# Cortex_M55 register map
Vendor: ARM Ltd.; File version: 1.2
CPU: CM55 r0p0, little endian, MPU, FPU, vendor SysTick, 8 interrupt priority bits
Registers are 32-bit, read-write, no defined reset value unless marked. A register's access mark holds for its fields unless they carry their own. Offsets are from the block's base; [hi:lo] are bit positions; {n}, {i} and the like mark numbered series; 'fields as' and 'values as' point back to an identical list.

## FPE — Floating Point Control Registers
Base 0xE000EF34
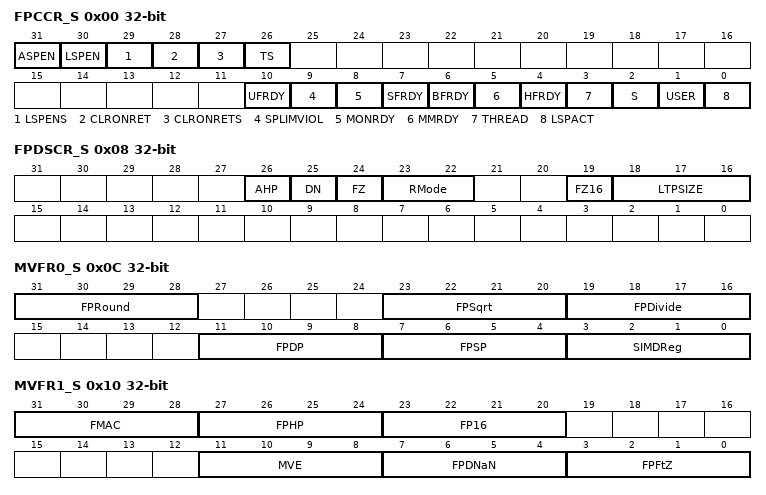
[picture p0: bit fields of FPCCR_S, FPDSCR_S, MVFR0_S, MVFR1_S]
0x00 FPCCR_S
  [31] ASPEN, [30] LSPEN, [29] LSPENS, [28] CLRONRET, [27] CLRONRETS, [26] TS, [10] UFRDY, [9] SPLIMVIOL, [8] MONRDY, [7] SFRDY, [6] BFRDY, [5] MMRDY, [4] HFRDY, [3] THREAD, [2] S, [1] USER, [0] LSPACT
0x04 FPCAR_S
  [31:3] ADDRESS
0x08 FPDSCR_S
  [26] AHP, [25] DN, [24] FZ, [23:22] RMode, [19] FZ16, [18:16] LTPSIZE
0x0C MVFR0_S ro
  [31:28] FPRound, [23:20] FPSqrt, [19:16] FPDivide, [11:8] FPDP, [7:4] FPSP, [3:0] SIMDReg
0x10 MVFR1_S ro
  [31:28] FMAC, [27:24] FPHP, [23:20] FP16, [11:8] MVE, [7:4] FPDNaN, [3:0] FPFtZ
0x14 MVFR2_S ro
  [7:4] FPMisc
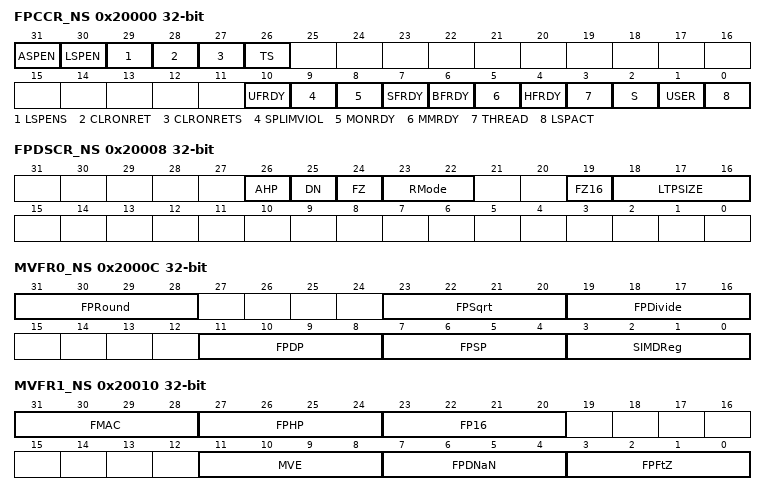
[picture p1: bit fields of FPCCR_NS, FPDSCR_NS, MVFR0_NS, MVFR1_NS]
0x20000 FPCCR_NS
  fields as FPCCR_S
0x20004 FPCAR_NS
  [31:3] ADDRESS
0x20008 FPDSCR_NS
  fields as FPDSCR_S
0x2000C MVFR0_NS ro
  fields as MVFR0_S
0x20010 MVFR1_NS ro
  fields as MVFR1_S
0x20014 MVFR2_NS ro
  [7:4] FPMisc

## ICB — Interrupt Control Registers
Base 0xE000E004
0x00 ICTR ro
  [3:0] INTLINESNUM
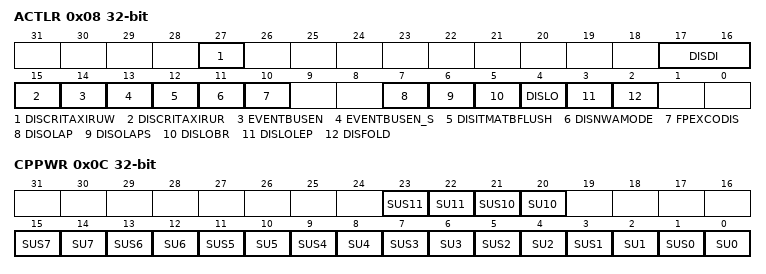
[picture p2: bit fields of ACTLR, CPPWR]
0x08 ACTLR
  [27] DISCRITAXIRUW, [17:16] DISDI, [15] DISCRITAXIRUR, [14] EVENTBUSEN, [13] EVENTBUSEN_S, [12] DISITMATBFLUSH, [11] DISNWAMODE, [10] FPEXCODIS, [7] DISOLAP, [6] DISOLAPS, [5] DISLOBR, [4] DISLO, [3] DISLOLEP, [2] DISFOLD
0x0C CPPWR
  [23] SUS11, [22] SU11, [21] SUS10, [20] SU10, [2n+1] SUS{n} (n=0..7), [2n] SU{n} (n=0..7)

## MPU — Memory protection Unit Control Registers
Base 0xE000ED90
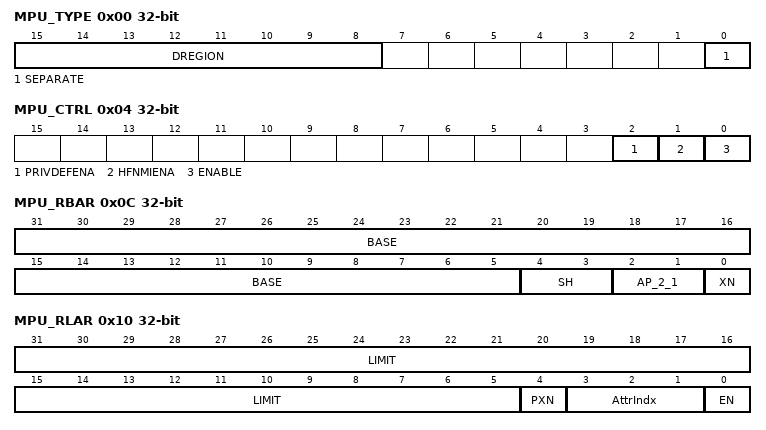
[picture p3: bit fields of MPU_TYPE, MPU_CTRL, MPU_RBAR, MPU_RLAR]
0x00 MPU_TYPE ro
  [15:8] DREGION
  [0] SEPARATE
    0=Uniform; 1=Separate
0x04 MPU_CTRL — MPU Control Register
  [2] PRIVDEFENA, [1] HFNMIENA, [0] ENABLE
0x08 MPU_RNR — MPU Region Number Register
  [7:0] REGION
0x0C MPU_RBAR — MPU Region Base Address Register
  [31:5] BASE, [4:3] SH, [2:1] AP_2_1, [0] XN
0x10 MPU_RLAR — MPU Region Limit Address Register
  [31:5] LIMIT, [4] PXN, [3:1] AttrIndx, [0] EN
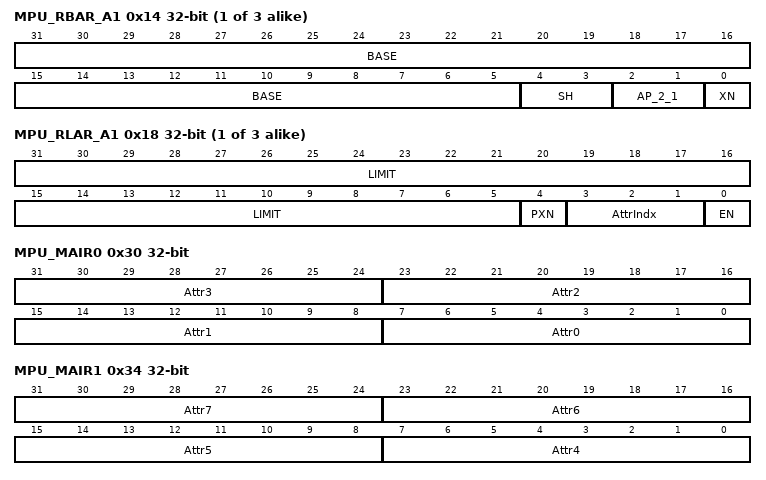
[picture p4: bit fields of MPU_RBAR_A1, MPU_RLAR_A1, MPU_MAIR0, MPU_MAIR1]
{0xC+8i} MPU_RBAR_A{i} (i=1..3) — MPU Region Base Address Register
  [31:5] BASE, [4:3] SH, [2:1] AP_2_1, [0] XN
{0x10+8i} MPU_RLAR_A{i} (i=1..3) — MPU Region Limit Address Register
  [31:5] LIMIT, [4] PXN, [3:1] AttrIndx, [0] EN
0x30 MPU_MAIR0 — MPU Memory Attribute Indirection Register 0
  [8n+7:8n] Attr{n} (n=0..3)
0x34 MPU_MAIR1 — MPU Memory Attribute Indirection Register 1
  [8n-25:8n-32] Attr{n} (n=4..7)
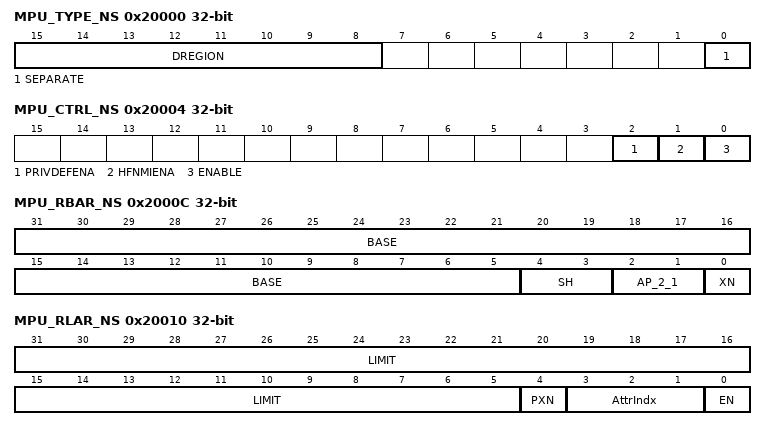
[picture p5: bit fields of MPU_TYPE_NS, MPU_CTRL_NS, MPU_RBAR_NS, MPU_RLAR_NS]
0x20000 MPU_TYPE_NS ro — MPU Type Register NS
  [15:8] DREGION
  [0] SEPARATE
    0=Uniform; 1=Separate
0x20004 MPU_CTRL_NS — MPU Control Register NS
  [2] PRIVDEFENA, [1] HFNMIENA, [0] ENABLE
0x20008 MPU_RNR_NS — MPU Region Number Register NS
  [7:0] REGION
0x2000C MPU_RBAR_NS — MPU Region Base Address Register NS
  [31:5] BASE, [4:3] SH, [2:1] AP_2_1, [0] XN
0x20010 MPU_RLAR_NS — MPU Region Limit Address Register NS
  [31:5] LIMIT, [4] PXN, [3:1] AttrIndx, [0] EN
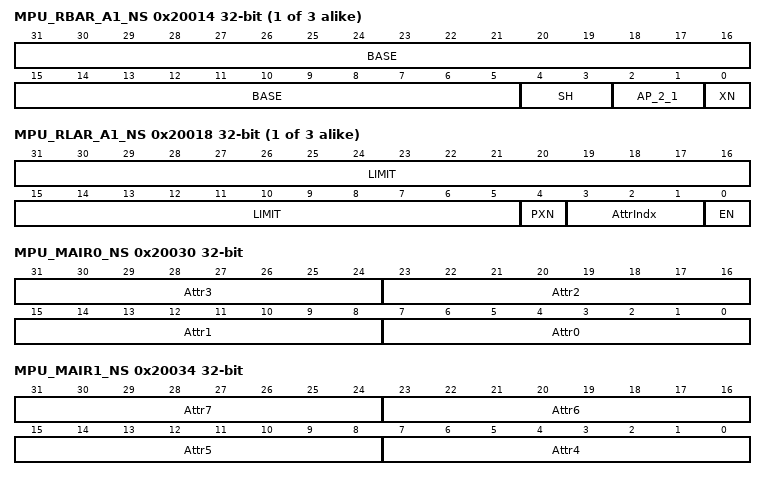
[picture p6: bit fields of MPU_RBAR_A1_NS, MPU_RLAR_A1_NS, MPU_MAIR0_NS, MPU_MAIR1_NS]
{0x2000C+8i} MPU_RBAR_A{i}_NS (i=1..3) — MPU Region Base Address Register NS
  [31:5] BASE, [4:3] SH, [2:1] AP_2_1, [0] XN
{0x20010+8i} MPU_RLAR_A{i}_NS (i=1..3) — MPU Region Limit Address Register NS
  [31:5] LIMIT, [4] PXN, [3:1] AttrIndx, [0] EN
0x20030 MPU_MAIR0_NS — MPU Memory Attribute Indirection Register 0 NS
  [8n+7:8n] Attr{n} (n=0..3)
0x20034 MPU_MAIR1_NS — MPU Memory Attribute Indirection Register 1 NS
  [8n-25:8n-32] Attr{n} (n=4..7)

## NVIC — Nested Vectored Interrupt Controller registers
Base 0xE000E100
{0x0+4i} NVIC_ISER{i} reset 0x0 (i=0..15) — Interrupt Set-Enable Register
  [31:0] SETENA
{0x80+4i} NVIC_ICER{i} reset 0x0 (i=0..15) — Interrupt Clear-Enable Register
  [31:0] CLRENA
{0x100+4i} NVIC_ISPR{i} reset 0x0 (i=0..15) — Interrupt Set-Pending Register
  [31:0] SETPEND
{0x180+4i} NVIC_ICPR{i} reset 0x0 (i=0..15) — Interrupt Clear-Pending Register
  [31:0] CLRPEND
{0x200+4i} NVIC_IABR{i} reset 0x0 (i=0..15) — Interrupt Active Bit Register
  [31:0] ACTIVE
{0x280+4i} ITNS{i} reset 0x0 (i=0..15) — Interrupt Target Non-secure Registers
  [31:0] ITNS
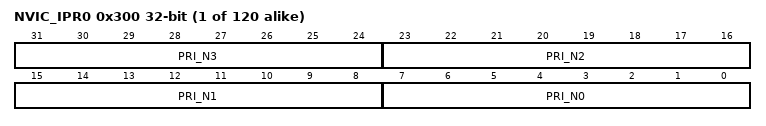
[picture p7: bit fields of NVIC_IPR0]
{0x300+4i} NVIC_IPR{i} (i=0..119)
  [8n+7:8n] PRI_N{n} (n=0..3)
0xE00 STIR ro
  [8:0] INTID

## SAU — Security Attribute Unit
Base 0xE000EDD0
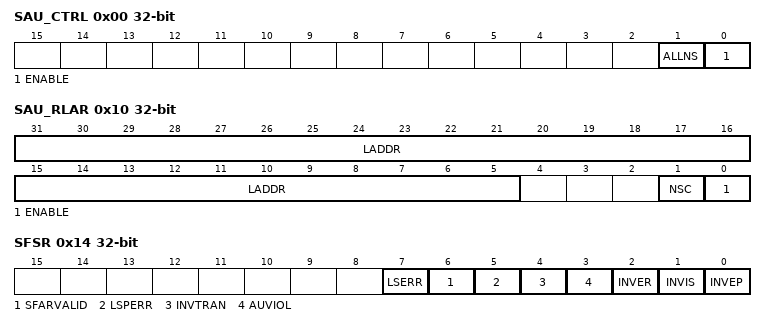
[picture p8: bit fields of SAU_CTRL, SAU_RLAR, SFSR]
0x00 SAU_CTRL
  [1] ALLNS, [0] ENABLE
0x04 SAU_TYPE ro
  [7:0] SREGION
0x08 SAU_RNR
  [7:0] REGION
0x0C SAU_RBAR
  [31:5] BADDR
0x10 SAU_RLAR
  [31:5] LADDR, [1] NSC, [0] ENABLE
0x14 SFSR
  [7] LSERR, [6] SFARVALID, [5] LSPERR, [4] INVTRAN, [3] AUVIOL, [2] INVER, [1] INVIS, [0] INVEP
0x18 SFAR
  [31:0] ADDRESS

## SIG — Software Interrupt Control
Base 0xE000EF00
0x00 STIR wo
  [8:0] INTID
0x20000 STIR_NS wo
  [8:0] INTID

## SYST — SysTick Control Registers
Base 0xE000E010
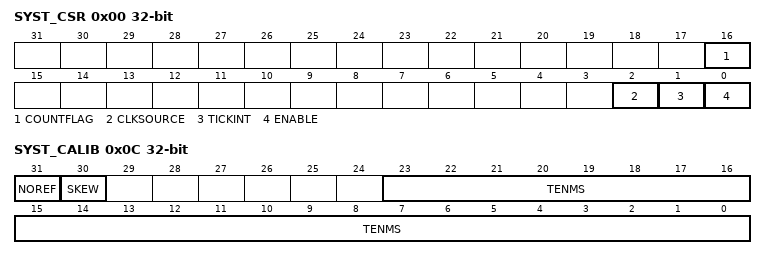
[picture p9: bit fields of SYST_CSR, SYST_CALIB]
0x00 SYST_CSR
  [16] COUNTFLAG, [2] CLKSOURCE, [1] TICKINT, [0] ENABLE
0x04 SYST_RVR
  [23:0] RELOAD
0x08 SYST_CVR
  [23:0] CURRENT
0x0C SYST_CALIB ro
  [31] NOREF, [30] SKEW, [23:0] TENMS
